# STM32H5E4xx register map
File version: 1.0
Registers are 32-bit, read-write, reset 0x0 unless marked. A register's access mark holds for its fields unless they carry their own. Offsets are from the block's base; [hi:lo] are bit positions; {n}, {i} and the like mark numbered series.

## DCMI
Base 0x4202C000
Same registers: DCMI_S 0x5202C000
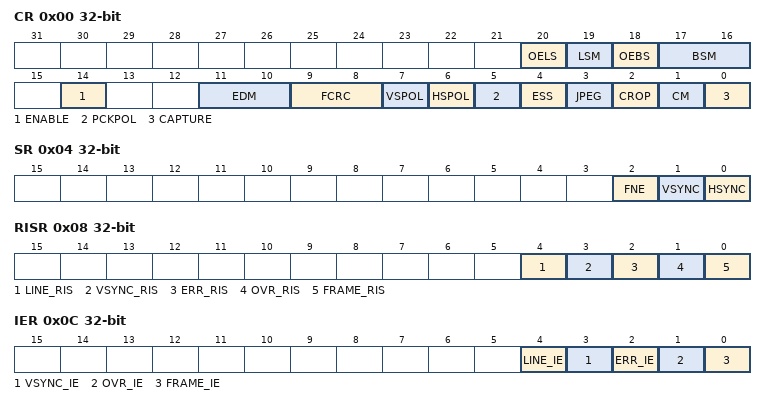
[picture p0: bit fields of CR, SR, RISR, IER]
0x00 CR — DCMI control register 1
  [20] OELS
  [19] LSM
  [18] OEBS
  [17:16] BSM
  [14] ENABLE
  [11:10] EDM — DCMI Extended data mode EDM[1:0]
  [9:8] FCRC — DCMI Frame capture rate control FCRC[1:0]
  [7] VSPOL
  [6] HSPOL
  [5] PCKPOL
  [4] ESS
  [3] JPEG
  [2] CROP
  [1] CM
  [0] CAPTURE
0x04 SR — DCMI status register
  [2] FNE, [1] VSYNC, [0] HSYNC
0x08 RISR — DCMI raw interrupt status register
  [4] LINE_RIS, [3] VSYNC_RIS, [2] ERR_RIS, [1] OVR_RIS, [0] FRAME_RIS
0x0C IER — DCMI interrupt enable register
  [4] LINE_IE, [3] VSYNC_IE, [2] ERR_IE, [1] OVR_IE, [0] FRAME_IE
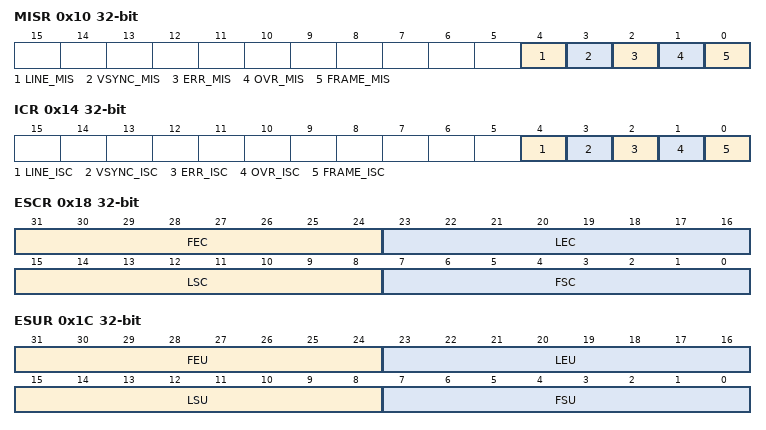
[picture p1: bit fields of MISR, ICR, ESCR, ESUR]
0x10 MISR — DCMI masked interrupt status register
  [4] LINE_MIS, [3] VSYNC_MIS, [2] ERR_MIS, [1] OVR_MIS, [0] FRAME_MIS
0x14 ICR — DCMI interrupt clear register
  [4] LINE_ISC, [3] VSYNC_ISC, [2] ERR_ISC, [1] OVR_ISC, [0] FRAME_ISC
0x18 ESCR — DCMI embedded synchronization code register
  [31:24] FEC, [23:16] LEC, [15:8] LSC, [7:0] FSC
0x1C ESUR — DCMI embedded synchronization unmask register
  [31:24] FEU, [23:16] LEU, [15:8] LSU, [7:0] FSU
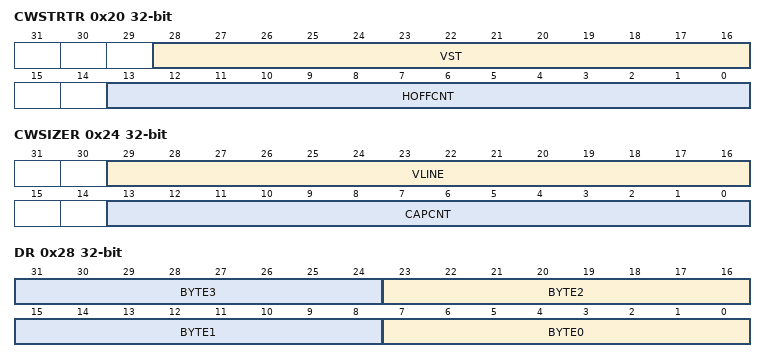
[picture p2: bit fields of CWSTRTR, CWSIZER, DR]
0x20 CWSTRTR — DCMI crop window start
  [28:16] VST, [13:0] HOFFCNT
0x24 CWSIZER — DCMI crop window size
  [29:16] VLINE, [13:0] CAPCNT
0x28 DR — DCMI data register
  [8n+7:8n] BYTE{n} (n=0..3)

## PSSI
Base 0x4202C400
Same registers: PSSI_S 0x5202C400
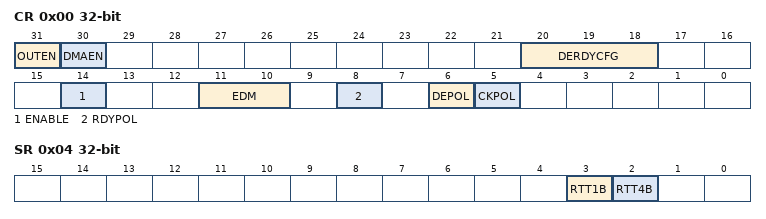
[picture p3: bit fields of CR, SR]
0x00 CR — PSSI control register
  [31] OUTEN — Data direction selection
  [30] DMAEN — DMA enable
  [20:18] DERDYCFG — Data enable and ready configuration
  [14] ENABLE — PSSI enable
  [11:10] EDM — Extended data mode
  [8] RDYPOL — Ready polarity
  [6] DEPOL — Data enable polarity
  [5] CKPOL — Parallel data clock polarity
0x04 SR — PSSI status register
  [3] RTT1B — Ready to transfer one byte
  [2] RTT4B — Ready to transfer four bytes
0x08 RIS — PSSI raw interrupt status register
  [1] OVR_RIS — Data buffer overrun/underrun raw interrupt status
0x0C IER — PSSI interrupt enable register
  [1] OVR_IE — Data buffer overrun/underrun interrupt enable
0x10 MIS — PSSI masked interrupt status register
  [1] OVR_MIS — Data buffer overrun/underrun masked interrupt status
0x14 ICR — PSSI interrupt clear register
  [1] OVR_ISC — Data buffer overrun/underrun interrupt status clear
0x28 DR — PSSI data register
  [31:0] DR — Data register

## HASH
Base 0x420C0400
Same registers: HASH_S 0x520C0400
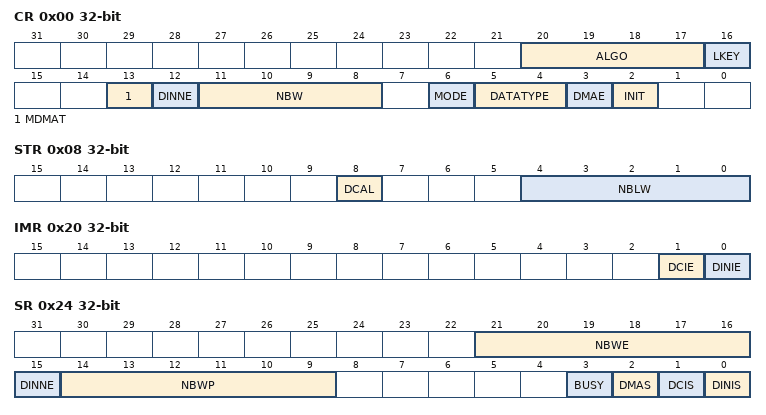
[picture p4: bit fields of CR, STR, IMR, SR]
0x00 CR — HASH control register
  [20:17] ALGO, [16] LKEY, [13] MDMAT, [12] DINNE, [11:8] NBW, [6] MODE, [5:4] DATATYPE, [3] DMAE, [2] INIT
0x04 DIN — HASH data input register
  [31:0] DATAIN
0x08 STR — HASH start register
  [8] DCAL, [4:0] NBLW
{0xC+4i} HRA{i} (i=0..4) — HASH digest registers
0x20 IMR — HASH interrupt enable register
  [1] DCIE, [0] DINIE
0x24 SR — HASH status register
  [21:16] NBWE, [15] DINNE, [14:9] NBWP, [3] BUSY, [2] DMAS, [1] DCIS, [0] DINIS
{0xF8+4i} CSR[{i}] (i=0..102)
{0x310+4i} HR{i} (i=0..41) — HASH digest registers

## RNG
Base 0x420C0800
Same registers: RNG_S 0x520C0800
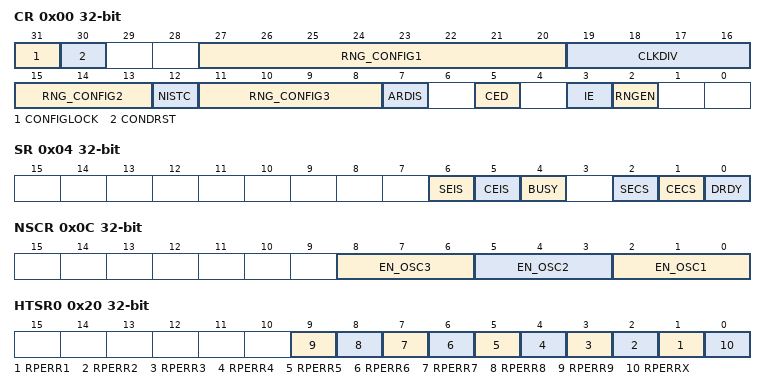
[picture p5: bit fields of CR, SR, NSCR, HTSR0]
0x00 CR — RNG control register
  [31] CONFIGLOCK — RNG configuration lock
  [30] CONDRST — Conditioning soft reset
  [27:20] RNG_CONFIG1 — RNG configuration 1
  [19:16] CLKDIV — Clock divider factor
    0=BY_1 (No clock division); 1=BY_2 (2 RNG clock cycles per internal RNG clock); 2=BY_4 (4 RNG clock cycles per internal RNG clock); 3=BY_8 (8 RNG clock cycles per internal RNG clock); 4=BY_16 (16 RNG clock cycles per internal RNG clock); 5=BY_32 (32 RNG clock cycles per internal RNG clock); 6=BY_64 (64 RNG clock cycles per internal RNG clock); 7=BY_128 (128 RNG clock cycles per internal RNG clock); 8=BY_256 (256 RNG clock cycles per internal RNG clock); 9=BY_512 (512 RNG clock cycles per internal RNG clock); 10=BY_1024 (1024 RNG clock cycles per internal RNG clock); 11=BY_2048 (2048 RNG clock cycles per internal RNG clock); 12=BY_4096 (4096 RNG clock cycles per internal RNG clock); 13=BY_8192 (8192 RNG clock cycles per internal RNG clock); 14=BY_16384 (16384 RNG clock cycles per internal RNG clock); 15=BY_32768 (32768 RNG clock cycles per internal RNG clock)
  [15:13] RNG_CONFIG2 — RNG configuration 2
  [12] NISTC — NIST custom
  [11:8] RNG_CONFIG3 — RNG configuration 3
  [7] ARDIS — Auto reset disable
  [5] CED — Clock error detection
  [3] IE — Interrupt enable
  [2] RNGEN — True random number generator enable
0x04 SR — RNG status register
  [6] SEIS, [5] CEIS, [4] BUSY, [2] SECS, [1] CECS, [0] DRDY
0x08 DR — RNG data register
0x0C NSCR — RNG noise source control register
  [8:6] EN_OSC3, [5:3] EN_OSC2, [2:0] EN_OSC1
{0x10+4i} HTCR{i} (i=0..3) — RNG health test configuration register
  [31:0] HTCFG
0x20 HTSR0 — RNG health test status register
  [n] RPERR{n} (n=1..9) — Repetitive error for oscillator i
  [0] RPERRX — Repetitive error after the XOR
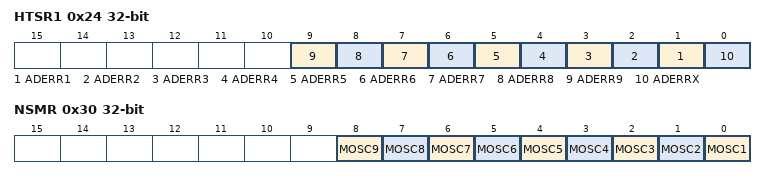
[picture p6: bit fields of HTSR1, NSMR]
0x24 HTSR1 — RNG health test status register
  [n] ADERR{n} (n=1..9) — Adaptative error for oscillator i
  [0] ADERRX — Adaptative error after the XOR
0x30 NSMR — RNG health test status register
  [n-1] MOSC{n} (n=1..9) — Mask oscillator i
